# MIMXRT1011 register map
Vendor: nxp.com; File version: 1.0
CPU: CM7 r0p1, little endian, MPU, FPU, VTOR, 4 interrupt priority bits
Registers are 32-bit, read-write, reset 0x0 unless marked. A register's access mark holds for its fields unless they carry their own. Offsets are from the block's base; [hi:lo] are bit positions; {n}, {i} and the like mark numbered series.

## XBARA — Crossbar Switch
Base 0x40098000; register names take the prefix XBARA_
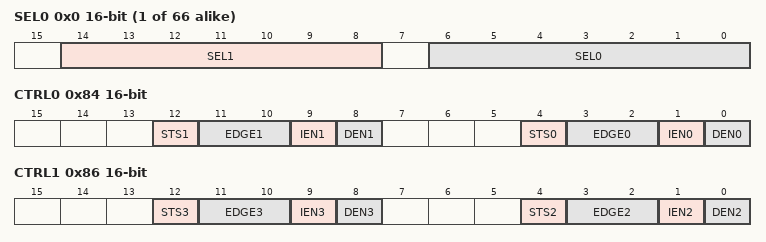
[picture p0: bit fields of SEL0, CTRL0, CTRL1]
{0x0+2i} SEL{i} 16-bit (i=0..65) — Crossbar A Select Register {i}
  [14:8] SEL{2i+1} — Input (XBARA_INn) to be muxed to XBARA_OUT{2i+1} (refer to Functional Description section for input/output assignment)
  [6:0] SEL{2i} — Input (XBARA_INn) to be muxed to XBARA_OUT{2i} (refer to Functional Description section for input/output assignment)
0x84 CTRL0 16-bit — Crossbar A Control Register 0
  [12] STS1 write-1-clears — Edge detection status for XBAR_OUT1
    0=Active edge not yet detected on XBAR_OUT1; 1=Active edge detected on XBAR_OUT1
  [11:10] EDGE1 — Active edge for edge detection on XBAR_OUT1
    0=STS1 never asserts; 1=STS1 asserts on rising edges of XBAR_OUT1; 2=STS1 asserts on falling edges of XBAR_OUT1; 3=STS1 asserts on rising and falling edges of XBAR_OUT1
  [9] IEN1 — Interrupt Enable for XBAR_OUT1
    0=Interrupt disabled; 1=Interrupt enabled
  [8] DEN1 — DMA Enable for XBAR_OUT1
    0=DMA disabled; 1=DMA enabled
  [4] STS0 write-1-clears — Edge detection status for XBAR_OUT0
    0=Active edge not yet detected on XBAR_OUT0; 1=Active edge detected on XBAR_OUT0
  [3:2] EDGE0 — Active edge for edge detection on XBAR_OUT0
    0=STS0 never asserts; 1=STS0 asserts on rising edges of XBAR_OUT0; 2=STS0 asserts on falling edges of XBAR_OUT0; 3=STS0 asserts on rising and falling edges of XBAR_OUT0
  [1] IEN0 — Interrupt Enable for XBAR_OUT0
    0=Interrupt disabled; 1=Interrupt enabled
  [0] DEN0 — DMA Enable for XBAR_OUT0
    0=DMA disabled; 1=DMA enabled
0x86 CTRL1 16-bit — Crossbar A Control Register 1
  [12] STS3 write-1-clears — Edge detection status for XBAR_OUT3
    0=Active edge not yet detected on XBAR_OUT3; 1=Active edge detected on XBAR_OUT3
  [11:10] EDGE3 — Active edge for edge detection on XBAR_OUT3
    0=STS3 never asserts; 1=STS3 asserts on rising edges of XBAR_OUT3; 2=STS3 asserts on falling edges of XBAR_OUT3; 3=STS3 asserts on rising and falling edges of XBAR_OUT3
  [9] IEN3 — Interrupt Enable for XBAR_OUT3
    0=Interrupt disabled; 1=Interrupt enabled
  [8] DEN3 — DMA Enable for XBAR_OUT3
    0=DMA disabled; 1=DMA enabled
  [4] STS2 write-1-clears — Edge detection status for XBAR_OUT2
    0=Active edge not yet detected on XBAR_OUT2; 1=Active edge detected on XBAR_OUT2
  [3:2] EDGE2 — Active edge for edge detection on XBAR_OUT2
    0=STS2 never asserts; 1=STS2 asserts on rising edges of XBAR_OUT2; 2=STS2 asserts on falling edges of XBAR_OUT2; 3=STS2 asserts on rising and falling edges of XBAR_OUT2
  [1] IEN2 — Interrupt Enable for XBAR_OUT2
    0=Interrupt disabled; 1=Interrupt enabled
  [0] DEN2 — DMA Enable for XBAR_OUT2
    0=DMA disabled; 1=DMA enabled

## IOMUXC_SNVS_GPR — IOMUXC
Base 0x400A4000; register names take the prefix IOMUXC_SNVS_GPR_
{0x0+4i} GPR{i} ro (i=0..2) — GPR{i} General Purpose Register
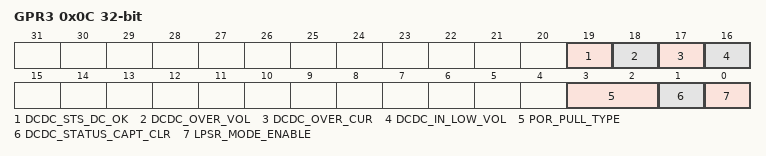
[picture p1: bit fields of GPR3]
0x0C GPR3 — GPR3 General Purpose Register
  [19] DCDC_STS_DC_OK ro — DCDC status OK
    0=DCDC is ramping up and not ready; 1=DCDC is ready
  [18] DCDC_OVER_VOL ro — DCDC output over voltage alert
    0=No over voltage detected; 1=Over voltage detected
  [17] DCDC_OVER_CUR ro — DCDC output over current alert
    0=No over current detected; 1=Over current detected
  [16] DCDC_IN_LOW_VOL ro — DCDC_IN low voltage detect.
    0=DCDC_IN is ok; 1=DCDC_IN is too low
  [3:2] POR_PULL_TYPE — POR_B pad control
    0=100 Ohm pull up enabled for POR_B always; 1=Disable pull in SNVS mode, 100 Ohm pull up enabled otherwise; 2=Disable pull of POR_B always; 3=100 Ohm pull down enabled in SNVS mode, 100 Ohm pull up enabled otherwise
  [1] DCDC_STATUS_CAPT_CLR — DCDC captured status clear
  [0] LPSR_MODE_ENABLE — Set to enable LPSR mode.
    0=SNVS domain will reset when system reset happens; 1=SNVS domain will only reset with SNVS POR
